AUTOSAR XML (schema 314)
package /ComponentType
  internal behavior Sa_CDDInterface9_InternalBehavior: component=Sa_CDDInterface9
    timing event CDDInterface9_Init1_InitEvent: start-on-event=CDDInterface9_Init1, period=0
    timing event TMT_CDDInterface9_Per1: start-on-event=CDDInterface9_Per1, period=0.002
    port-api-options:
      enable-take-address=false, indirect-api=false, port=ADCMtrCurr1
      enable-take-address=false, indirect-api=false, port=ADCMtrCurr2
      enable-take-address=false, indirect-api=false, port=CDDPorts
      enable-take-address=false, indirect-api=false, port=CorrectedElecMtrPos
      enable-take-address=false, indirect-api=false, port=CorrMtrCurrPosition
      enable-take-address=false, indirect-api=false, port=CorrMtrPosElec
      enable-take-address=false, indirect-api=false, port=CumMechMtrPos
      enable-take-address=false, indirect-api=false, port=Die1RxError
      enable-take-address=false, indirect-api=false, port=Die1RxMtrPos
      enable-take-address=false, indirect-api=false, port=Die1RxRevCtr
      enable-take-address=false, indirect-api=false, port=Die1UnderVoltgFltAccum
      enable-take-address=false, indirect-api=false, port=Die2RxError
      enable-take-address=false, indirect-api=false, port=Die2RxMtrPos
      enable-take-address=false, indirect-api=false, port=Die2RxRevCtr
      enable-take-address=false, indirect-api=false, port=ExpectedOnTimeA
      enable-take-address=false, indirect-api=false, port=ExpectedOnTimeB
      enable-take-address=false, indirect-api=false, port=ExpectedOnTimeC
      enable-take-address=false, indirect-api=false, port=IgnCnt
      enable-take-address=false, indirect-api=false, port=LRPRPhaseadvanceCaptured
      enable-take-address=false, indirect-api=false, port=MeasuredOnTimeA
      enable-take-address=false, indirect-api=false, port=MeasuredOnTimeB
      enable-take-address=false, indirect-api=false, port=MeasuredOnTimeC
      enable-take-address=false, indirect-api=false, port=MEC
      enable-take-address=false, indirect-api=false, port=MechMtrPos1
      enable-take-address=false, indirect-api=false, port=MechMtrPos1Timestamp
      enable-take-address=false, indirect-api=false, port=MechMtrPos2Timestamp
      enable-take-address=false, indirect-api=false, port=ModIdxFinal
      enable-take-address=false, indirect-api=false, port=MtrCurrDax
      enable-take-address=false, indirect-api=false, port=MtrCurrK1
      enable-take-address=false, indirect-api=false, port=MtrCurrK2
      enable-take-address=false, indirect-api=false, port=MtrCurrQax
      enable-take-address=false, indirect-api=false, port=MtrCurrQaxFinalRef
      enable-take-address=false, indirect-api=false, port=MtrVoltDax
      enable-take-address=false, indirect-api=false, port=MtrVoltQax
      enable-take-address=false, indirect-api=false, port=RxMtrPosParityAccum
      enable-take-address=false, indirect-api=false, port=SysCCorrMtrPosElec
      enable-take-address=false, indirect-api=false, port=SysCVSwitchADC
      enable-take-address=false, indirect-api=false, port=UncorrMechMtrPos1
    runnable CDDInterface9_Init1
      data write access WRITE_IgnCnt_Cnt_u16: data-element=IgnCnt.Cnt_u16
      data write access WRITE_MEC_Cnt_enum: data-element=MEC.Cnt_enum
    runnable CDDInterface9_Per1
      35 x data write access:
        WRITE_ADCMtrCurr1_Volts_f32: data-element=ADCMtrCurr1.Volts_f32
        WRITE_ADCMtrCurr2_Volts_f32: data-element=ADCMtrCurr2.Volts_f32
        WRITE_CorrectedElecMtrPos_Rev_u0p16: data-element=CorrectedElecMtrPos.Rev_u0p16
        WRITE_CorrMtrCurrPosition_Rev_f32: data-element=CorrMtrCurrPosition.Rev_f32
        WRITE_CorrMtrPosElec_Rev_f32: data-element=CorrMtrPosElec.Rev_f32
        WRITE_CumMechMtrPos_Rev_f32: data-element=CumMechMtrPos.Rev_f32
        WRITE_Die1RxError_Cnt_u16: data-element=Die1RxError.Cnt_u16
        WRITE_Die1RxMtrPos_Cnt_u16: data-element=Die1RxMtrPos.Cnt_u16
        WRITE_Die1RxRevCtr_Cnt_u16: data-element=Die1RxRevCtr.Cnt_u16
        WRITE_Die1UnderVoltgFltAccum_Cnt_u16: data-element=Die1UnderVoltgFltAccum.Cnt_u16
        WRITE_Die2RxError_Cnt_u16: data-element=Die2RxError.Cnt_u16
        WRITE_Die2RxMtrPos_Cnt_u16: data-element=Die2RxMtrPos.Cnt_u16
        WRITE_Die2RxRevCtr_Cnt_u16: data-element=Die2RxRevCtr.Cnt_u16
        WRITE_ExpectedOnTimeA_Cnt_u32: data-element=ExpectedOnTimeA.Cnt_u32
        WRITE_ExpectedOnTimeB_Cnt_u32: data-element=ExpectedOnTimeB.Cnt_u32
        WRITE_ExpectedOnTimeC_Cnt_u32: data-element=ExpectedOnTimeC.Cnt_u32
        WRITE_LRPRPhaseadvanceCaptured_Cnt_s16: data-element=LRPRPhaseadvanceCaptured.Cnt_s16
        WRITE_MeasuredOnTimeA_Cnt_u32: data-element=MeasuredOnTimeA.Cnt_u32
        WRITE_MeasuredOnTimeB_Cnt_u32: data-element=MeasuredOnTimeB.Cnt_u32
        WRITE_MeasuredOnTimeC_Cnt_u32: data-element=MeasuredOnTimeC.Cnt_u32
        WRITE_MechMtrPos1_Rev_f32: data-element=MechMtrPos1.Rev_f32
        WRITE_MechMtrPos1Timestamp_USec_u32: data-element=MechMtrPos1Timestamp.USec_u32
        WRITE_MechMtrPos2Timestamp_USec_u32: data-element=MechMtrPos2Timestamp.USec_u32
        WRITE_ModIdxFinal_Uls_f32: data-element=ModIdxFinal.Uls_f32
        WRITE_MtrCurrDax_Amp_f32: data-element=MtrCurrDax.Amp_f32
        WRITE_MtrCurrK1_Amp_f32: data-element=MtrCurrK1.Amp_f32
        WRITE_MtrCurrK2_Amp_f32: data-element=MtrCurrK2.Amp_f32
        WRITE_MtrCurrQax_Amp_f32: data-element=MtrCurrQax.Amp_f32
        WRITE_MtrCurrQaxFinalRef_Amp_f32: data-element=MtrCurrQaxFinalRef.Amp_f32
        WRITE_MtrVoltDax_Volt_f32: data-element=MtrVoltDax.Volt_f32
        WRITE_MtrVoltQax_Volt_f32: data-element=MtrVoltQax.Volt_f32
        WRITE_RxMtrPosParityAccum_Cnt_u16: data-element=RxMtrPosParityAccum.Cnt_u16
        WRITE_SysCCorrMtrPosElec_Rev_f32: data-element=SysCCorrMtrPosElec.Rev_f32
        WRITE_SysCVSwitchADC_Cnt_u16: data-element=SysCVSwitchADC.Cnt_u16
        WRITE_UncorrMechMtrPos1_Rev_u0p16: data-element=UncorrMechMtrPos1.Rev_u0p16
      sync call SC_CDDPorts_ClearPhsReasSum: operation=CDDPorts.ClearPhsReasSum, timeout=0
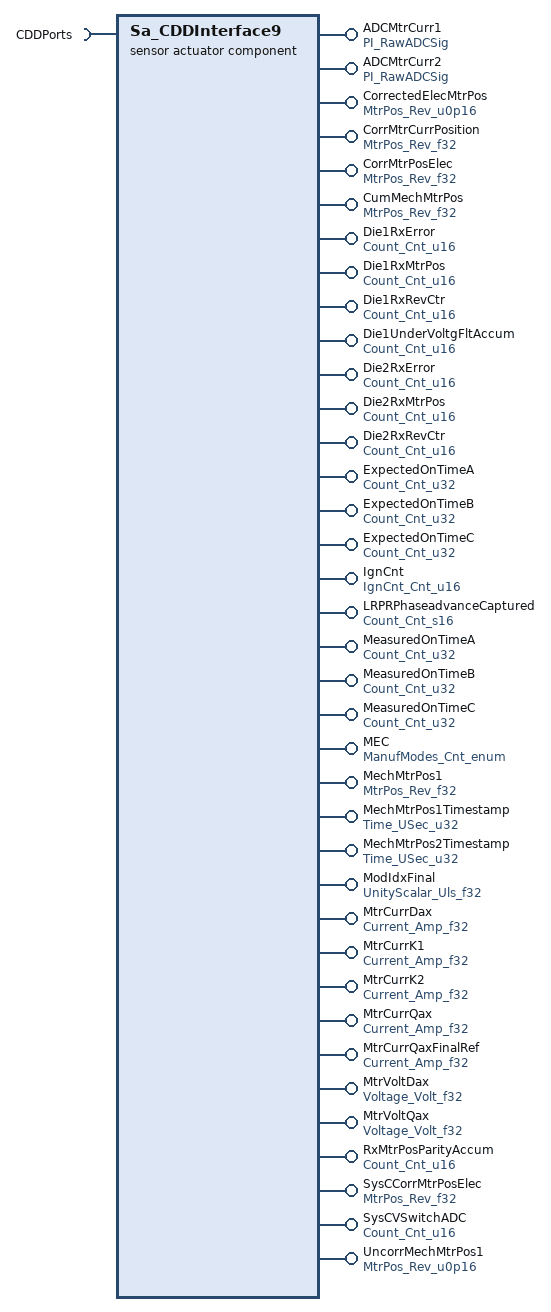
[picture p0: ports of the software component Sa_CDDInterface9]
  sensor actuator software component type Sa_CDDInterface9
    37 x provide port:
      ADCMtrCurr1: unqueued-sender-com-spec{data-element=Volts_f32, can-invalidate=false, init-value=D_ZERO_ULS_F32}, provided-interface=PI_RawADCSig
      ADCMtrCurr2: unqueued-sender-com-spec{data-element=Volts_f32, can-invalidate=false, init-value=D_ZERO_ULS_F32}, provided-interface=PI_RawADCSig
      CorrectedElecMtrPos: unqueued-sender-com-spec{data-element=Rev_u0p16, can-invalidate=false, init-value=D_ZERO_CNT_U16}, provided-interface=MtrPos_Rev_u0p16
      CorrMtrCurrPosition: unqueued-sender-com-spec{data-element=Rev_f32, can-invalidate=false, init-value=D_ZERO_ULS_F32}, provided-interface=MtrPos_Rev_f32
      CorrMtrPosElec: unqueued-sender-com-spec{data-element=Rev_f32, can-invalidate=false, init-value=D_ZERO_ULS_F32}, provided-interface=MtrPos_Rev_f32
      CumMechMtrPos: unqueued-sender-com-spec{data-element=Rev_f32, can-invalidate=false, init-value=D_ZERO_ULS_F32}, provided-interface=MtrPos_Rev_f32
      Die1RxError: unqueued-sender-com-spec{data-element=Cnt_u16, can-invalidate=false, init-value=D_ZERO_CNT_U16}, provided-interface=Count_Cnt_u16
      Die1RxMtrPos: unqueued-sender-com-spec{data-element=Cnt_u16, can-invalidate=false, init-value=D_ZERO_CNT_U16}, provided-interface=Count_Cnt_u16
      Die1RxRevCtr: unqueued-sender-com-spec{data-element=Cnt_u16, can-invalidate=false, init-value=D_ZERO_CNT_U16}, provided-interface=Count_Cnt_u16
      Die1UnderVoltgFltAccum: unqueued-sender-com-spec{data-element=Cnt_u16, can-invalidate=false, init-value=D_ZERO_CNT_U16}, provided-interface=Count_Cnt_u16
      Die2RxError: unqueued-sender-com-spec{data-element=Cnt_u16, can-invalidate=false, init-value=D_ZERO_CNT_U16}, provided-interface=Count_Cnt_u16
      Die2RxMtrPos: unqueued-sender-com-spec{data-element=Cnt_u16, can-invalidate=false, init-value=D_ZERO_CNT_U16}, provided-interface=Count_Cnt_u16
      Die2RxRevCtr: unqueued-sender-com-spec{data-element=Cnt_u16, can-invalidate=false, init-value=D_ZERO_CNT_U16}, provided-interface=Count_Cnt_u16
      ExpectedOnTimeA: unqueued-sender-com-spec{data-element=Cnt_u32, can-invalidate=false, init-value=D_ZERO_CNT_U32}, provided-interface=Count_Cnt_u32
      ExpectedOnTimeB: unqueued-sender-com-spec{data-element=Cnt_u32, can-invalidate=false, init-value=D_ZERO_CNT_U32}, provided-interface=Count_Cnt_u32
      ExpectedOnTimeC: unqueued-sender-com-spec{data-element=Cnt_u32, can-invalidate=false, init-value=D_ZERO_CNT_U32}, provided-interface=Count_Cnt_u32
      IgnCnt: unqueued-sender-com-spec{data-element=Cnt_u16, can-invalidate=false, init-value=D_ZERO_CNT_U16}, provided-interface=IgnCnt_Cnt_u16
      LRPRPhaseadvanceCaptured: unqueued-sender-com-spec{data-element=Cnt_s16, can-invalidate=false, init-value=D_ZERO_CNT_S16}, provided-interface=Count_Cnt_s16
      MeasuredOnTimeA: unqueued-sender-com-spec{data-element=Cnt_u32, can-invalidate=false, init-value=D_ZERO_CNT_U32}, provided-interface=Count_Cnt_u32
      MeasuredOnTimeB: unqueued-sender-com-spec{data-element=Cnt_u32, can-invalidate=false, init-value=D_ZERO_CNT_U32}, provided-interface=Count_Cnt_u32
      MeasuredOnTimeC: unqueued-sender-com-spec{data-element=Cnt_u32, can-invalidate=false, init-value=D_ZERO_CNT_U32}, provided-interface=Count_Cnt_u32
      MEC: unqueued-sender-com-spec{data-element=Cnt_enum, can-invalidate=false, init-value=D_MANUFMODEINIT_CNT_ENUM}, provided-interface=ManufModes_Cnt_enum
      MechMtrPos1: unqueued-sender-com-spec{data-element=Rev_f32, can-invalidate=false, init-value=D_ZERO_ULS_F32}, provided-interface=MtrPos_Rev_f32
      MechMtrPos1Timestamp: unqueued-sender-com-spec{data-element=USec_u32, can-invalidate=false, init-value=D_ZERO_CNT_U32}, provided-interface=Time_USec_u32
      MechMtrPos2Timestamp: unqueued-sender-com-spec{data-element=USec_u32, can-invalidate=false, init-value=D_ZERO_CNT_U32}, provided-interface=Time_USec_u32
      ModIdxFinal: unqueued-sender-com-spec{data-element=Uls_f32, can-invalidate=false, init-value=D_ZERO_ULS_F32}, provided-interface=UnityScalar_Uls_f32
      MtrCurrDax: unqueued-sender-com-spec{data-element=Amp_f32, can-invalidate=false, init-value=D_ZERO_ULS_F32}, provided-interface=Current_Amp_f32
      MtrCurrK1: unqueued-sender-com-spec{data-element=Amp_f32, can-invalidate=false, init-value=D_ZERO_ULS_F32}, provided-interface=Current_Amp_f32
      MtrCurrK2: unqueued-sender-com-spec{data-element=Amp_f32, can-invalidate=false, init-value=D_ZERO_ULS_F32}, provided-interface=Current_Amp_f32
      MtrCurrQax: unqueued-sender-com-spec{data-element=Amp_f32, can-invalidate=false, init-value=D_ZERO_ULS_F32}, provided-interface=Current_Amp_f32
      MtrCurrQaxFinalRef: unqueued-sender-com-spec{data-element=Amp_f32, can-invalidate=false, init-value=D_ZERO_ULS_F32}, provided-interface=Current_Amp_f32
      MtrVoltDax: unqueued-sender-com-spec{data-element=Volt_f32, can-invalidate=false, init-value=D_ZERO_ULS_F32}, provided-interface=Voltage_Volt_f32
      MtrVoltQax: unqueued-sender-com-spec{data-element=Volt_f32, can-invalidate=false, init-value=D_ZERO_ULS_F32}, provided-interface=Voltage_Volt_f32
      RxMtrPosParityAccum: unqueued-sender-com-spec{data-element=Cnt_u16, can-invalidate=false, init-value=D_ZERO_CNT_U16}, provided-interface=Count_Cnt_u16
      SysCCorrMtrPosElec: unqueued-sender-com-spec{data-element=Rev_f32, can-invalidate=false, init-value=D_ZERO_ULS_F32}, provided-interface=MtrPos_Rev_f32
      SysCVSwitchADC: unqueued-sender-com-spec{data-element=Cnt_u16, can-invalidate=false, init-value=D_ZERO_CNT_U16}, provided-interface=Count_Cnt_u16
      UncorrMechMtrPos1: unqueued-sender-com-spec{data-element=Rev_u0p16, can-invalidate=false, init-value=D_ZERO_CNT_U16}, provided-interface=MtrPos_Rev_u0p16
    require port CDDPorts: required-com-specs=[ApplyMtrElecMechPol, ClearPhsReasSum], required-interface=CDDPorts
  swc implementation Sa_CDDInterface9_Implementation: behavior=Sa_CDDInterface9_InternalBehavior
    code-descriptors:
      code Code: type=SRC
